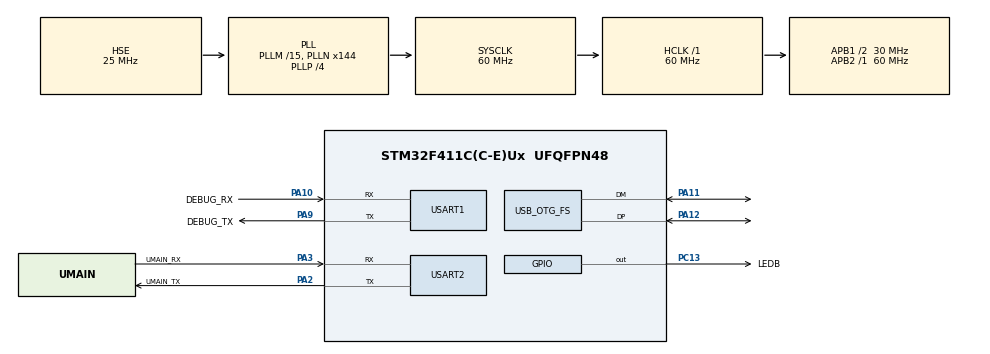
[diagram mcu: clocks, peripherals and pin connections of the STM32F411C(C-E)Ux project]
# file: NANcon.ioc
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Mcu.Family=STM32F4
Mcu.Name=STM32F411C(C-E)Ux
Mcu.Package=UFQFPN48
NVIC.OTG_FS_IRQn=true\:0\:0\:false\:false\:true\:false\:true
NVIC.PriorityGroup=NVIC_PRIORITYGROUP_4
NVIC.TIM3_IRQn=true\:0\:0\:false\:false\:true\:true\:true
NVIC.USART2_IRQn=true\:0\:0\:false\:false\:true\:true\:true
PA10.GPIO_Label=DEBUG_RX
PA10.GPIO_Speed=GPIO_SPEED_FREQ_HIGH
PA10.Mode=Asynchronous
PA10.Signal=USART1_RX
PA11.Mode=Device_Only
PA11.Signal=USB_OTG_FS_DM
PA12.Mode=Device_Only
PA12.Signal=USB_OTG_FS_DP
PA2.GPIO_Label=UMAIN_TX
PA2.GPIO_Speed=GPIO_SPEED_FREQ_HIGH
PA2.Mode=Asynchronous
PA2.Signal=USART2_TX
PA3.GPIO_Label=UMAIN_RX
PA3.GPIO_Speed=GPIO_SPEED_FREQ_HIGH
PA3.Mode=Asynchronous
PA3.Signal=USART2_RX
PA9.GPIO_Label=DEBUG_TX
PA9.GPIO_Speed=GPIO_SPEED_FREQ_HIGH
PA9.Mode=Asynchronous
PA9.Signal=USART1_TX
PC13-ANTI_TAMP.GPIO_Label=LEDB
PC13-ANTI_TAMP.PinState=GPIO_PIN_SET
PC13-ANTI_TAMP.Signal=GPIO_Output
PH0\ -\ OSC_IN.Mode=HSE-External-Oscillator
PH0\ -\ OSC_IN.Signal=RCC_OSC_IN
PH1\ -\ OSC_OUT.Mode=HSE-External-Oscillator
PH1\ -\ OSC_OUT.Signal=RCC_OSC_OUT
ProjectManager.HeapSize=0x200
ProjectManager.StackSize=0x400
ProjectManager.TargetToolchain=MDK-ARM V5
RCC.48MHZClocksFreq_Value=48000000
RCC.AHBFreq_Value=60000000
RCC.APB1CLKDivider=RCC_HCLK_DIV2
RCC.APB1Freq_Value=30000000
RCC.APB1TimFreq_Value=60000000
RCC.APB2Freq_Value=60000000
RCC.APB2TimFreq_Value=60000000
RCC.CortexFreq_Value=60000000
RCC.HCLKFreq_Value=60000000
RCC.HSE_VALUE=25000000
RCC.HSI_VALUE=16000000
RCC.LSE_VALUE=32768
RCC.PLLM=15
RCC.PLLN=144
RCC.PLLP=RCC_PLLP_DIV4
RCC.PLLQ=5
RCC.SYSCLKFreq_VALUE=60000000
RCC.SYSCLKSource=RCC_SYSCLKSOURCE_PLLCLK
RCC.VCOOutputFreq_Value=240000000
USART1.VirtualMode=VM_ASYNC
USART2.VirtualMode=VM_ASYNC
USB_DEVICE.CLASS_NAME_FS=CUSTOM_HID
USB_DEVICE.USBD_CUSTOMHID_OUTREPORT_BUF_SIZE=30
USB_DEVICE.USBD_CUSTOM_HID_REPORT_DESC_SIZE=6
USB_DEVICE.VirtualMode=CustomHid
USB_DEVICE.VirtualModeFS=Custom_Hid_FS
USB_OTG_FS.VirtualMode=Device_Only
VP_TIM3_VS_ClockSourceINT.Mode=Internal
VP_USB_DEVICE_VS_USB_DEVICE_CUSTOM_HID_FS.Mode=CUSTOM_HID_FS
board=custom

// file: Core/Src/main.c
/* USER CODE BEGIN Header */
/**
  ******************************************************************************
  * @file           : main.c
  * @brief          : Main program body
  ******************************************************************************
  * @attention
  *
  * Copyright (c) 2022 STMicroelectronics.
  * All rights reserved.
  *
  * This software is licensed under terms that can be found in the LICENSE file
  * in the root directory of this software component.
  * If no LICENSE file comes with this software, it is provided AS-IS.
  *
  ******************************************************************************
  */
/* USER CODE END Header */
#include "main.h"
#include "usb_device.h"

TIM_HandleTypeDef htim3;

UART_HandleTypeDef huart1;
UART_HandleTypeDef huart2;

/* USER CODE BEGIN PV */
const char *TAG_INIT = "[INIT]";
/* USER CODE END PV */

void SystemClock_Config(void);
static void MX_GPIO_Init(void);
static void MX_TIM3_Init(void);
static void MX_USART1_UART_Init(void);
static void MX_USART2_UART_Init(void);

int main(void)
{

  /* MCU Configuration--------------------------------------------------------*/

  /* Reset of all peripherals, Initializes the Flash interface and the Systick. */
  HAL_Init();

  /* Configure the system clock */
  SystemClock_Config();

  /* Initialize all configured peripherals */
  MX_GPIO_Init();
  MX_TIM3_Init();
  MX_USART1_UART_Init();
  MX_USART2_UART_Init();
  MX_USB_DEVICE_Init();
  /* USER CODE BEGIN 2 */

  HIDInit();                    //NNK: 初始化USBD
	ledb_test();		  	          //NNK: led测试
	tim3_nvic_init();             //NNK: 初始化计时器3中断
	EasyCon_script_init();
	umain_nvic_init();            //NNK: 初始化主串口中断

	// start script at start
	EasyCon_script_start();

  /* Infinite loop */
  /* USER CODE BEGIN WHILE */
  while (1)
  {
		// Process local script instructions.
		EasyCon_script_task();

		// send report
		HIDTask();
  }
  /* USER CODE END 3 */
}

void SystemClock_Config(void)
{
  RCC_OscInitTypeDef RCC_OscInitStruct = {0};
  RCC_ClkInitTypeDef RCC_ClkInitStruct = {0};

  /** Configure the main internal regulator output voltage
  */
  __HAL_RCC_PWR_CLK_ENABLE();
  __HAL_PWR_VOLTAGESCALING_CONFIG(PWR_REGULATOR_VOLTAGE_SCALE2);
  /** Initializes the RCC Oscillators according to the specified parameters
  * in the RCC_OscInitTypeDef structure.
  */
  RCC_OscInitStruct.OscillatorType = RCC_OSCILLATORTYPE_HSE;
  RCC_OscInitStruct.HSEState = RCC_HSE_ON;
  RCC_OscInitStruct.PLL.PLLState = RCC_PLL_ON;
  RCC_OscInitStruct.PLL.PLLSource = RCC_PLLSOURCE_HSE;
  RCC_OscInitStruct.PLL.PLLM = 15;
  RCC_OscInitStruct.PLL.PLLN = 144;
  RCC_OscInitStruct.PLL.PLLP = RCC_PLLP_DIV4;
  RCC_OscInitStruct.PLL.PLLQ = 5;
  if (HAL_RCC_OscConfig(&RCC_OscInitStruct) != HAL_OK)
  {
    Error_Handler();
  }
  /** Initializes the CPU, AHB and APB buses clocks
  */
  RCC_ClkInitStruct.ClockType = RCC_CLOCKTYPE_HCLK|RCC_CLOCKTYPE_SYSCLK
                              |RCC_CLOCKTYPE_PCLK1|RCC_CLOCKTYPE_PCLK2;
  RCC_ClkInitStruct.SYSCLKSource = RCC_SYSCLKSOURCE_PLLCLK;
  RCC_ClkInitStruct.AHBCLKDivider = RCC_SYSCLK_DIV1;
  RCC_ClkInitStruct.APB1CLKDivider = RCC_HCLK_DIV2;
  RCC_ClkInitStruct.APB2CLKDivider = RCC_HCLK_DIV1;

  if (HAL_RCC_ClockConfig(&RCC_ClkInitStruct, FLASH_LATENCY_1) != HAL_OK)
  {
    Error_Handler();
  }
}

static void MX_TIM3_Init(void)
{

  TIM_ClockConfigTypeDef sClockSourceConfig = {0};
  TIM_MasterConfigTypeDef sMasterConfig = {0};

  htim3.Instance = TIM3;
  htim3.Init.Prescaler = (TIM_Freq * 100) - 1;                    //NNK: 设置预分频值，使得单次向上计数输出为0.1ms
  htim3.Init.CounterMode = TIM_COUNTERMODE_UP;
  htim3.Init.Period = TIM_SingleTickTime - 1;                     //NNK: 设置重装载值，使得每次时钟中断输出为1ms
  htim3.Init.ClockDivision = TIM_CLOCKDIVISION_DIV1;
  htim3.Init.AutoReloadPreload = TIM_AUTORELOAD_PRELOAD_DISABLE;
  if (HAL_TIM_Base_Init(&htim3) != HAL_OK)
  {
    Error_Handler();
  }
  sClockSourceConfig.ClockSource = TIM_CLOCKSOURCE_INTERNAL;
  if (HAL_TIM_ConfigClockSource(&htim3, &sClockSourceConfig) != HAL_OK)
  {
    Error_Handler();
  }
  sMasterConfig.MasterOutputTrigger = TIM_TRGO_RESET;
  sMasterConfig.MasterSlaveMode = TIM_MASTERSLAVEMODE_DISABLE;
  if (HAL_TIMEx_MasterConfigSynchronization(&htim3, &sMasterConfig) != HAL_OK)
  {
    Error_Handler();
  }

}

static void MX_USART1_UART_Init(void)
{

  huart1.Instance = USART1;
  huart1.Init.BaudRate = 115200;
  huart1.Init.WordLength = UART_WORDLENGTH_8B;
  huart1.Init.StopBits = UART_STOPBITS_1;
  huart1.Init.Parity = UART_PARITY_NONE;
  huart1.Init.Mode = UART_MODE_TX_RX;
  huart1.Init.HwFlowCtl = UART_HWCONTROL_NONE;
  huart1.Init.OverSampling = UART_OVERSAMPLING_16;
  if (HAL_UART_Init(&huart1) != HAL_OK)
  {
    Error_Handler();
  }

}

static void MX_USART2_UART_Init(void)
{

  huart2.Instance = USART2;
  huart2.Init.BaudRate = 9600;
  huart2.Init.WordLength = UART_WORDLENGTH_8B;
  huart2.Init.StopBits = UART_STOPBITS_1;
  huart2.Init.Parity = UART_PARITY_NONE;
  huart2.Init.Mode = UART_MODE_TX_RX;
  huart2.Init.HwFlowCtl = UART_HWCONTROL_NONE;
  huart2.Init.OverSampling = UART_OVERSAMPLING_16;
  if (HAL_UART_Init(&huart2) != HAL_OK)
  {
    Error_Handler();
  }

}

static void MX_GPIO_Init(void)
{
  GPIO_InitTypeDef GPIO_InitStruct = {0};

  /* GPIO Ports Clock Enable */
  __HAL_RCC_GPIOC_CLK_ENABLE();
  __HAL_RCC_GPIOH_CLK_ENABLE();
  __HAL_RCC_GPIOA_CLK_ENABLE();

  /*Configure GPIO pin Output Level */
  HAL_GPIO_WritePin(LEDB_GPIO_Port, LEDB_Pin, GPIO_PIN_SET);

  /*Configure GPIO pin : LEDB_Pin */
  GPIO_InitStruct.Pin = LEDB_Pin;
  GPIO_InitStruct.Mode = GPIO_MODE_OUTPUT_PP;
  GPIO_InitStruct.Pull = GPIO_NOPULL;
  GPIO_InitStruct.Speed = GPIO_SPEED_FREQ_HIGH;
  HAL_GPIO_Init(LEDB_GPIO_Port, &GPIO_InitStruct);

}

void Error_Handler(void)
{
  __disable_irq();
  while (1)
  {
  }
}
